# STM32WL5X_CM0P register map
File version: 2.1
CPU: CM0 r0p1, little endian, MPU, no FPU, 4 interrupt priority bits
Registers are 32-bit, read-write, reset 0x0 unless marked. A register's access mark holds for its fields unless they carry their own. Offsets are from the block's base; [hi:lo] are bit positions; 'fields as' and 'values as' point back to an identical list.

## FLASH
Base 0x58004000
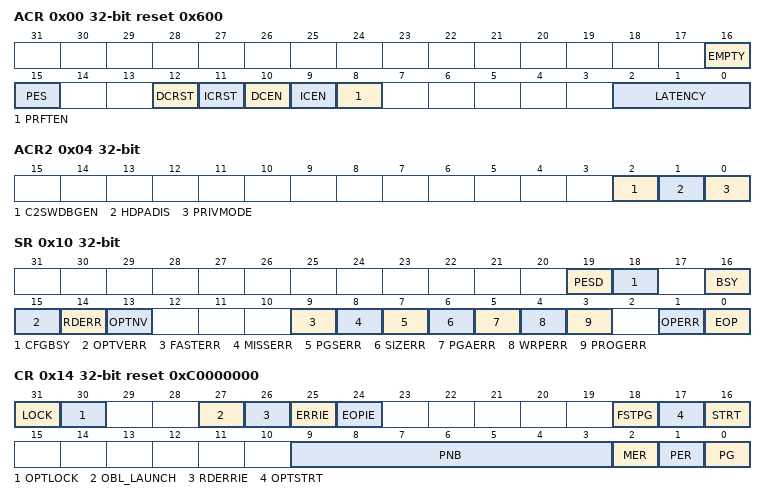
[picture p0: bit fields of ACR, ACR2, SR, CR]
0x00 ACR reset 0x600 — Access control register
  [16] EMPTY — Flash User area empty
    0=Programmed (User Flash programmend); 1=Empty (User Flash empty)
  [15] PES — CPU1 programm erase suspend request
    0=Granted (Flash program and erase operations granted); 1=Suspended (Any new Flash program and erase operation is suspended until this bit is cleared. The PESD bit in FLASH_SR is set when PES bit in FLASH_ACR is set)
  [12] DCRST — Data cache reset
    0=NotReset (Data cache is not reset); 1=Reset (Data cache is reset)
  [11] ICRST — Instruction cache reset
    0=NotReset (Instruction cache is not reset); 1=Reset (Instruction cache is reset)
  [10] DCEN — Data cache enable
    0=Disabled (Data cache is disabled); 1=Enabled (Data cache is enabled)
  [9] ICEN — Instruction cache enable
    0=Disabled (Instruction cache is disabled); 1=Enabled (Instruction cache is enabled)
  [8] PRFTEN — Prefetch enable
    0=Disabled (Prefetch is disabled); 1=Enabled (Prefetch is enabled)
  [2:0] LATENCY
    0=WS0 (0 wait states); 1=WS1 (1 wait states); 2=WS2 (2 wait states)
0x04 ACR2 — Flash access control register 2
  [2] C2SWDBGEN — CPU2 Software debug enable
  [1] HDPADIS — Flash user hide protection area access disable
  [0] PRIVMODE — CFI privileged mode enable
0x08 KEYR wo — Flash key register
  [31:0] KEY
0x0C OPTKEYR wo — Option byte key register
  [31:0] OPTKEY — Option byte key
0x10 SR access per field — Status register
  [19] PESD ro — Programming / erase operation suspended
    0=Granted (Flash program and erase operations granted); 1=Suspended (Any new Flash program and erase operation is suspended until this bit is cleared. This bit is set when the PES bit in FLASH_ACR is set)
  [18] CFGBSY ro — Programming or erase configuration busy
    0=Free (PG, PNB, PER, MER bits available for writing); 1=Busy (PG, PNB, PER, MER bits not available for writing (operation ongoing))
  [16] BSY ro — Busy
    0=Inactive (No write/erase operation is in progress); 1=Active (No write/erase operation is in progress)
  [15] OPTVERR rw — Option validity error
    on read: 0=No error in option and engineering bits; 1=Error in option and engineering bits | on write: 1=Clear the flag
  [14] RDERR rw — PCROP read error
    on read: 0=NoError (No read-only error happened); 1=Error (Read-only error happened) | on write: 1=Clear the flag
  [13] OPTNV ro — User Option OPTIVAL indication
    0=Valid (The OBL user option OPTVAL indicates "valid"); 1=Invalid (The OBL user option OPTVAL indicates "invalid")
  [9] FASTERR rw — Fast programming error
    on read: 0=NoError (No fast programming error happened); 1=Error (Fast programming error happened) | on write: 1=Clear the flag
  [8] MISSERR rw — Fast programming data miss error
    on read: 0=NoError (No fast programming data miss error happened); 1=Error (Fast programming data miss error happened) | on write: 1=Clear the flag
  [7] PGSERR rw — Programming sequence error
    on read: 0=NoError (No fast programming sequence error happened); 1=Error (Fast programming sequence error happened) | on write: 1=Clear the flag
  [6] SIZERR rw — Size error
    on read: 0=NoError (No size error happened); 1=Error (Size error happened) | on write: 1=Clear the flag
  [5] PGAERR rw — Programming alignment error
    on read: 0=NoError (No programming alignment error happened); 1=Error (Programming alignment error happened) | on write: 1=Clear the flag
  [4] WRPERR rw — Write protected error
    on read: 0=NoError (No write protection error happened); 1=Error (Write protection error happened) | on write: 1=Clear the flag
  [3] PROGERR rw — Programming error
    on read: 0=NoError (No size programming error happened); 1=Error (Programming error happened) | on write: 1=Clear the flag
  [1] OPERR rw — Operation error
    on read: 0=NoError (No memory opreation error happened); 1=Error (Memory operation error happened) | on write: 1=Clear the flag
  [0] EOP rw — End of operation
    on read: 0=NoEvent (No EOP operation occurred); 1=Event (An EOP event occurred) | on write: 1=Clear the flag
0x14 CR reset 0xC0000000 — Flash control register
  [31] LOCK — FLASH_CR Lock
    on read: 0=Unlocked (FLASH_CR is unlocked) | on write: 1=Locked (FLASH_CR is locked)
  [30] OPTLOCK — Options Lock
    on read: 0=Unlocked (FLASH_CR options are unlocked) | on write: 1=Locked (FLASH_CR options are locked)
  [27] OBL_LAUNCH — Force the option byte loading
    on read: 0=Complete (Option byte loaded); 1=NotComplete (Option byte loading to be done) | on write: 1=Reload option byte
  [26] RDERRIE — PCROP read error interrupt enable
    0=Disabled (PCROP read error interrupt disable); 1=Enabled (PCROP read error interrupt enable)
  [25] ERRIE — Error interrupt enable
    0=Disabled (OPERR Error interrupt disable); 1=Enabled (OPERR Error interrupt enable)
  [24] EOPIE — End of operation interrupt enable
    0=Disabled (End of program interrupt disable); 1=Enabled (End of program interrupt enable)
  [18] FSTPG — Fast programming
    0=Disabled (Fast programming disabled); 1=Enabled (Fast programming enabled)
  [17] OPTSTRT — Options modification start
    on read: 0=Done (Options modification completed or idle) | on write: 1=Start (Trigger options programming operation)
  [16] STRT — Start
    values as OPTSTRT
  [9:3] PNB — Page number
  [2] MER — Mass erase
    0=NoErase (No mass erase); 1=MassErase (Trigger mass erase)
  [1] PER — Page erase
    0=Disabled (Page erase disabled); 1=Enabled (Page erase enabled)
  [0] PG — Programming
    0=Disabled (Flash programming disabled); 1=Enabled (Flash programming enabled)
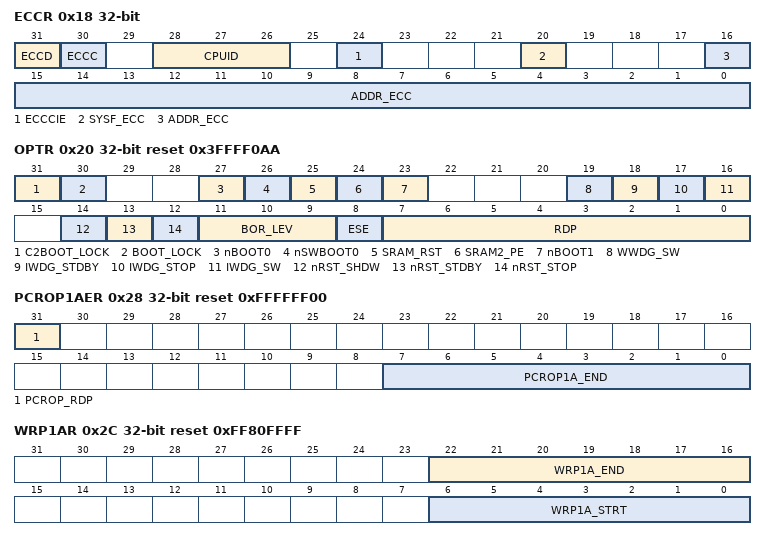
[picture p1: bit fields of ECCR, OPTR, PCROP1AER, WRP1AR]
0x18 ECCR access per field — Flash ECC register
  [31] ECCD rw — ECC detection
    on read: 0=NoEvent (Two ECC errors detected); 1=Event (No two ECC errors detected) | on write: 1=Clear the flag
  [30] ECCC rw — ECC correction
    on read: 0=NoEvent (ECC error corrected); 1=Event (No ECC error corrected) | on write: 1=Clear the flag
  [28:26] CPUID ro — CPU identification
  [24] ECCCIE rw — ECC correction interrupt enable
    0=Disabled (ECCC interrupt disabled); 1=Enabled (ECCC interrupt enabled)
  [20] SYSF_ECC ro — System Flash ECC fail
    0=NotInFlash (No System Flash memory ECC fail); 1=InFlash (System Flash memory ECC fail)
  [16:0] ADDR_ECC ro — ECC fail address
0x20 OPTR reset 0x3FFFF0AA — Flash option register
  [31] C2BOOT_LOCK — CPU2 CM0+ Unique Boot entry enable option bit
  [30] BOOT_LOCK — CPU1 CM4 Unique Boot entry enable option bit
    0=Disabled (Boot lock is disabled); 1=Enabled (Boot lock is enabled)
  [27] nBOOT0 — nBOOT0 option bit
    0=Clear (When nSWBOOT0 is cleared, select boot mode together with nBOOT1); 1=Set (When nSWBOOT0 is cleared, select boot mode together with nBOOT1)
  [26] nSWBOOT0 — Software BOOT0 selection
    0=Bit (BOOT0 taken from nBOOT0 in this register); 1=Pin (BOOT0 taken from GPIO PH3/BOOT0)
  [25] SRAM_RST — SRAM2 Erase when system reset
    0=Reset (SRAM1 and SRAM2 erased when a system reset occurs); 1=NotReset (SRAM1 and SRAM2 not erased when a system reset occurs)
  [24] SRAM2_PE — SRAM2 parity check enable
    0=Enabled (SRAM2 Parity check enabled); 1=Disabled (SRAM2 Parity check disabled)
  [23] nBOOT1 — Boot configuration
    0=Clear (When nSWBOOT0 is cleared, select boot mode together with nBOOT0); 1=Set (When nSWBOOT0 is cleared, select boot mode together with nBOOT0)
  [19] WWDG_SW — Window watchdog selection
    0=Hardware window watchdog; 1=Software window watchdog
  [18] IWDG_STDBY — Independent watchdog counter freeze in Standby mode
    0=Frozen (Independent watchdog counter frozen in Standby mode); 1=Running (Independent watchdog counter running in Standby mode)
  [17] IWDG_STOP — Independent watchdog counter freeze in Stop mode
    0=Frozen (Independent watchdog counter frozen in Stop mode); 1=Running (Independent watchdog counter running in Stop mode)
  [16] IWDG_SW — Independent watchdog selection
    0=Hardware independent watchdog; 1=Software independent watchdog
  [14] nRST_SHDW
    0=Enabled (Reset generated when entering the Shutdown mode); 1=Disabled (No reset generated when entering the Shutdown mode)
  [13] nRST_STDBY
    0=Enabled (Reset generated when entering the Standby mode); 1=Disabled (No reset generated when entering the Standby mode)
  [12] nRST_STOP
    values as nRST_STDBY
  [11:9] BOR_LEV — BOR reset Level
    0=Level0 (BOR level 0. Reset level threshold is around 1.7 V); 1=Level1 (BOR level 1. Reset level threshold is around 2.0 V); 2=Level2 (BOR level 2. Reset level threshold is around 2.2 V); 3=Level3 (BOR level 3. Reset level threshold is around 2.5 V); 4=Level4 (BOR level 4. Reset level threshold is around 2.8 V)
  [8] ESE — System security enabled flag
    0=Disabled (Security disabled); 1=Enabled (Security enabled)
  [7:0] RDP — Read protection level
    136=Level 1, memories readout protection active (writes 0x88); 170=Level 0, readout protection not active; 204=Level 2, chip readout protection active
0x24 PCROP1ASR reset 0xFFFFFFFF — Flash PCROP zone A Start address register
  [7:0] PCROP1A_STRT — PCROP1A area start offset
0x28 PCROP1AER reset 0xFFFFFF00 — Flash PCROP zone A End address register
  [31] PCROP_RDP — PCROP area preserved when RDP level decreased
  [7:0] PCROP1A_END — PCROP area end offset
0x2C WRP1AR reset 0xFF80FFFF — Flash WRP area A address register
  [22:16] WRP1A_END — Bank 1 WRP first area A end offset
  [6:0] WRP1A_STRT — Bank 1 WRP first area start offset
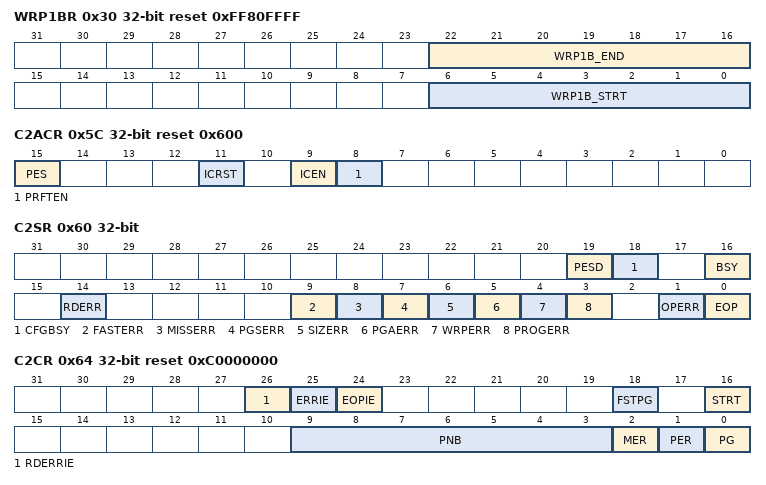
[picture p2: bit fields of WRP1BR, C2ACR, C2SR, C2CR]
0x30 WRP1BR reset 0xFF80FFFF — Flash WRP area B address register
  [22:16] WRP1B_END — Bank 1 WRP second area B start offset
  [6:0] WRP1B_STRT — Bank 1 WRP second area B end offset
0x34 PCROP1BSR reset 0xFFFFFFFF — Flash PCROP zone B Start address register
  [7:0] PCROP1B_STRT — Bank 1 WRP second area B end offset
0x38 PCROP1BER reset 0xFFFFFF00 — Flash PCROP zone B End address register
  [7:0] PCROP1B_END — PCROP1B area end offset
0x3C IPCCBR reset 0xFFFFFFFF — Flash IPCC data buffer address register
  [13:0] IPCCDBA
0x5C C2ACR reset 0x600 — Flash CPU2 access control register
  [15] PES — CPU2 program / erase suspend request
    0=Granted (Flash program and erase operations granted); 1=Suspended (Any new Flash program and erase operation is suspended until this bit is cleared. The PESD bit in FLASH_C2SR is set when PES bit in FLASH_C2ACR is set)
  [11] ICRST — CPU2 Instruction cache reset
    0=NotReset (CPU2 instruction cache is not reset); 1=Reset (CPU2 instruction cache is reset)
  [9] ICEN — CPU2 Instruction cache enable
    0=Disabled (CPU2 instruction cache is disabled); 1=Enabled (CPU2 instruction cache is enabled)
  [8] PRFTEN — CPU2 Prefetch enable
    0=Disabled (CPU2 prefetch is disabled); 1=Enabled (CPU2 prefetch is enabled)
0x60 C2SR access per field — Flash CPU2 status register
  [19] PESD ro
    0=Granted (Flash program and erase operations granted); 1=Suspended (Any new Flash program and erase operation is suspended until this bit is cleared. This bit is set when at least one PES bit in FLASH_ACR or FLASH_C2ACR is set.)
  [18] CFGBSY ro
    values as SR.CFGBSY
  [16] BSY ro
    values as SR.BSY
  [14] RDERR rw — PCROP read error
    values as SR.RDERR
  [9] FASTERR rw — Fast programming error
    values as SR.FASTERR
  [8] MISSERR rw — Fast programming data miss error
    values as SR.MISSERR
  [7] PGSERR rw — Programming sequence error
    values as SR.PGSERR
  [6] SIZERR rw — Size error
    values as SR.SIZERR
  [5] PGAERR rw
    values as SR.PGAERR
  [4] WRPERR rw
    values as SR.WRPERR
  [3] PROGERR rw — Programming error
    values as SR.PROGERR
  [1] OPERR rw — Operation error
    values as SR.OPERR
  [0] EOP rw — End of operation
    values as SR.EOP
0x64 C2CR reset 0xC0000000 — Flash CPU2 control register
  [26] RDERRIE
    values as CR.RDERRIE
  [25] ERRIE — Error interrupt enable
    values as CR.ERRIE
  [24] EOPIE — End of operation interrupt enable
    values as CR.EOPIE
  [18] FSTPG — Fast programming
    values as CR.FSTPG
  [16] STRT — Start
    values as CR.OPTSTRT
  [9:3] PNB — Page number selection
  [2] MER — Mass erase
    0=NoErase (No mass erase); 1=MassErase (Trigger mass erase)
  [1] PER — Page erase
    values as CR.PER
  [0] PG — Programming
    values as CR.PG
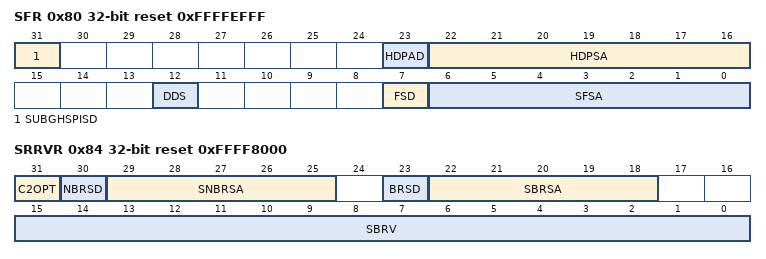
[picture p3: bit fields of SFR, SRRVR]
0x80 SFR reset 0xFFFFEFFF — Flash secure Flash start address register
  [31] SUBGHSPISD — sub-GHz radio SPI security disable
    0=Enabled (sub-GHz radio SPI security enabled); 1=Disabled (sub-GHz radio SPI security disabled)
  [23] HDPAD — User Flash hide protection area disabled
    0=Enabled (User Flash memory hide protection area enabled. HDPSA[6:0] contains the start address of the first 2-Kbyte page of the user Flash memory hide protection area); 1=Disabled (User Flash memory hide protection area disabled)
  [22:16] HDPSA — User Flash hide protection area start address
  [12] DDS
    0=Enabled (CPU2 debug access enabled); 1=Disabled (CPU2 debug access disabled)
  [7] FSD — Flash security disabled
    0=Secure (System and Flash memory secure); 1=NonSecure (System and Flash memory non-secure)
  [6:0] SFSA — Secure Flash start address
0x84 SRRVR reset 0xFFFF8000 — Flash secure SRAM start address and CPU2 reset vector register
  [31] C2OPT
    0=SRAM (SBRV offset addresses SRAM1 or SRAM2, from start address 0x2000_0000 + SBRV); 1=Flash (SBRV offset addresses the Flash memory, from start address 0x0800_0000 + SBRV)
  [30] NBRSD
    0=Secure (SRAM1 is secure. SNBRSA[4:0] contains the start address of the first 1-Kbyte page of the secure non-backup SRAM1 area); 1=NonSecure (SRAM1 is non-secure)
  [29:25] SNBRSA — Secure non-backup SRAM1 start address
  [23] BRSD — backup SRAM2 security disable
    0=Secure (SRAM2 is secure. SNBRSA[4:0] contains the start address of the first 1-Kbyte page of the secure backup SRAM2 area); 1=NonSecure (SRAM2 is non-secure)
  [22:18] SBRSA — Secure backup SRAM2 start address
  [15:0] SBRV — CPU2 boot reset vector
